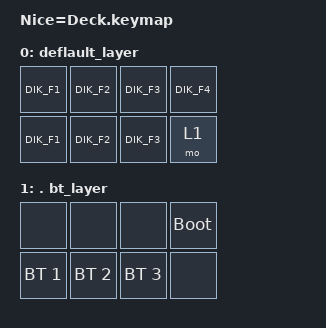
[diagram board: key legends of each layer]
#include <behaviors.dtsi>
#include <dt-bindings/zmk/keys.h>
#include <dt-bindings/zmk/bt.h>

/ {..
    keymap {
        compatible = "zmk,keymap";

        deflault_layer {
            bindings = <
                &kp DIK_F1    .&kp DIK_F2    .&kp DIK_F3    .&kp DIK_F4
                &kp DIK_F1    .&kp DIK_F2    .&kp DIK_F3    .&mo 1
            >;
        };.
        
        bt_layer {
            bindings = <
                &none            &none            &none            &bootloader
                &bt BT_SEL 1            &bt BT_SEL 2            &bt BT_SEL 3            &none
            >;
        };
    };
};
